# STM32H743 register map
File version: 2.4
CPU: CM7 r0p1, little endian, MPU, FPU, 4 interrupt priority bits
Registers are 32-bit, read-write, reset 0x0 unless marked. A register's access mark holds for its fields unless they carry their own. Offsets are from the block's base; [hi:lo] are bit positions; {n}, {i} and the like mark numbered series; <NAME> marks a mode.

## MDMA — MDMA（主 DMA 控制器）
Base 0x52000000
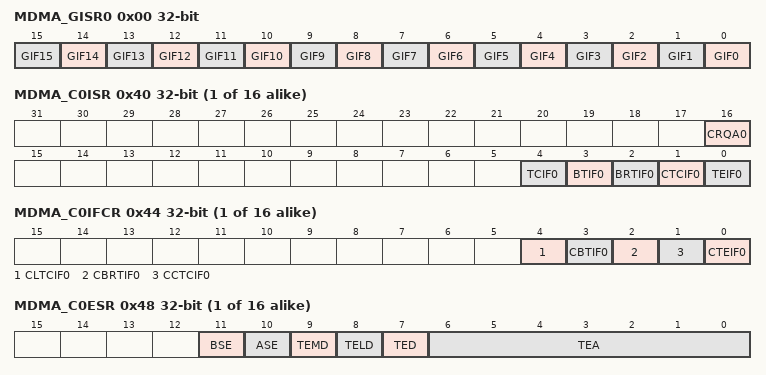
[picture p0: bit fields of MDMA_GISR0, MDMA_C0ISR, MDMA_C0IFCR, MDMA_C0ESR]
0x00 MDMA_GISR0 ro — MDMA 全局中断/状态寄存器
  [n] GIF{n} (n=0..15) — 通道 x 全局中断标志（x=...）。此位由硬件置位与复位。它是对应通道 x 所有已使能中断标志（CTCIFx、BTIFx、BRTIFx、TEIFx）的逻辑或，这些标志在中断屏蔽寄存器（CTCIEx、BTIEx、BRTIEx、TEIEx）中使能后生效。
{0x40+0x40*i} MDMA_C{i}ISR ro (i=0..15) — MDMA 通道 x 中断/状态寄存器
  [16] CRQA{i} — 通道 x 请求活跃标志
  [4] TCIF{i} — 通道 x 缓冲区传输完成
  [3] BTIF{i} — 通道 x 块传输完成中断标志。此位由硬件置位。软件向 DMA_IFCRy 寄存器的对应位写 1 可将其清零。
  [2] BRTIF{i} — 通道 x 块重复传输完成中断标志。此位由硬件置位。软件向 DMA_IFCRy 寄存器的对应位写 1 可将其清零。
  [1] CTCIF{i} — 通道 x 通道传输完成中断标志。此位由硬件置位。软件向 DMA_IFCRy 寄存器的对应位写 1 可将其清零。当最后一个块传输完成且通道已自动禁用时，CTC 置位。当通道因 EN 位写 0 而挂起时，CTC 同样置位。
  [0] TEIF{i} — 通道 x 传输错误中断标志。此位由硬件置位。软件向 DMA_IFCRy 寄存器的对应位写 1 可将其清零。
{0x44+0x40*i} MDMA_C{i}IFCR wo (i=0..15) — MDMA 通道 x 中断标志清除寄存器
  [4] CLTCIF{i} — 通道 x 清除缓冲区传输完成中断标志。向此位写 1 可将 MDMA_ISRy 寄存器中的 TCIFx 清零。
  [3] CBTIF{i} — 通道 x 清除块传输完成中断标志。向此位写 1 可将 MDMA_ISRy 寄存器中的 BTIFx 清零。
  [2] CBRTIF{i} — 通道 x 清除块重复传输完成中断标志。向此位写 1 可将 MDMA_ISRy 寄存器中的 BRTIFx 清零。
  [1] CCTCIF{i} — 通道 x 清除通道传输完成中断标志。向此位写 1 可将 MDMA_ISRy 寄存器中的 CTCIFx 清零。
  [0] CTEIF{i} — 通道 x 清除传输错误中断标志。向此位写 1 可将 MDMA_ISRy 寄存器中的 TEIFx 清零。
{0x48+0x40*i} MDMA_C{i}ESR ro (i=0..15) — MDMA 通道 x 错误状态寄存器
  [11] BSE — 块大小错误。当块大小不是源端或目的端数据大小的整数倍时，此位由硬件置位。TED 将指示问题在源端还是目的端。软件向 DMA_IFCRy 寄存器中的 CTEIFx 位写 1 可将其清零。
  [10] ASE — 地址/大小错误。当编程地址与数据大小不对齐时，此位由硬件置位。TED 将指示问题在源端还是目的端。软件向 DMA_IFCRy 寄存器中的 CTEIFx 位写 1 可将其清零。
  [9] TEMD — 传输错误（掩码数据）。当写入掩码数据发生传输错误时，此位由硬件置位。软件向 DMA_IFCRy 寄存器中的 CTEIFx 位写 1 可将其清零。
  [8] TELD — 传输错误（链接数据）。当读取块链接数据结构发生传输错误时，此位由硬件置位。软件向 DMA_IFCRy 寄存器中的 CTEIFx 位写 1 可将其清零。
  [7] TED — 传输错误方向。在 MDMA 数据传输发生错误时，此位由硬件置位与清零。
  [6:0] TEA — 传输错误地址。在 MDMA 数据传输发生错误时，这些位由硬件置位与清零，与 TED 配合使用。该字段指示引发传输/访问错误的地址的低 7 位。软件可将其（截断至缓冲区传输长度大小）与当前 SAR/DAR 值相加来还原故障地址。注意：由于 FIFO 管理机制，SAR/DAR 当前值并不反映该最后地址。SAR/DAR 仅在（缓冲区）传完 TLEN+1 字节后才更新。注意：发生链接数据错误时此字段不会置位。
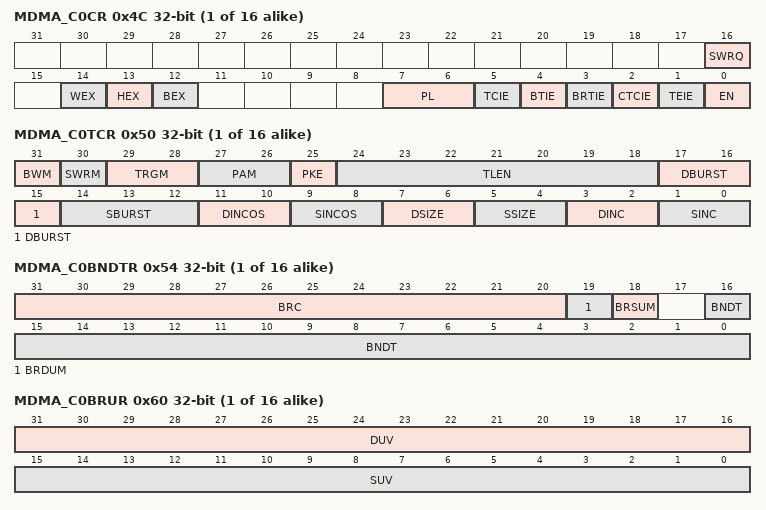
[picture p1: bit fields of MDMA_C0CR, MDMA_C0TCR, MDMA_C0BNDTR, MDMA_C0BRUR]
{0x4C+0x40*i} MDMA_C{i}CR access per field (i=0..15) — 此寄存器用于控制相应通道。
  [16] SWRQ wo — 软件请求。向此位写 1 将使 MDMA_ISRy 寄存器中的 CRQAx 置位，从而激活通道 x 的请求。注意：可通过整个 CxCR 寄存器或地址偏移为 0x4E + 0x40*通道号的 8 位/16 位寄存器来激活 SWRQ。在软件请求的情况下，不会产生应答信号（无硬件信号，也不进行 CxMAR 写访问）。
  [14] WEX rw — 字端序交换
  [13] HEX rw — 半字端序交换
  [12] BEX rw — 字节端序交换
  [7:6] PL rw — 优先级。这些位由软件置位与清零。这些位受保护，仅当 EN 为 0 时才可写入。
  [5] TCIE rw — 缓冲区传输完成中断使能。此位由软件置位与清零。
  [4] BTIE rw — 块传输中断使能。此位由软件置位与清零。
  [3] BRTIE rw — 块重复传输中断使能。此位由软件置位与清零。
  [2] CTCIE rw — 通道传输完成中断使能。此位由软件置位与清零。
  [1] TEIE rw — 传输错误中断使能。此位由软件置位与清零。
  [0] EN rw — 通道使能
{0x50+0x40*i} MDMA_C{i}TCR (i=0..15) — 此寄存器用于配置相应通道。
  [31] BWM — 缓冲写模式。此位由软件置位与清零。此位受保护，仅当 EN 为 0 时才可写入。注意：所有 MDMA 目的端访问均为不可缓存访问。
  [30] SWRM — 软件请求模式。此位由软件置位与清零。若当前有硬件或软件请求处于活跃状态，此位的变更将延迟到当前传输完成之后。若 CxMAR 包含有效地址，CxMDR 的值也将写入 CxMAR 地址。此位受保护，仅当 EN 为 0 时才可写入。
  [29:28] TRGM — 触发模式。这些位由软件置位与清零。注意：若当前块的 TRGM 为 11，则通过链接列表机制在当前块结束时加载的所有值必须保持相同的 TRGM=11 值和相同的 SWRM 值，否则结果未定义。这些位受保护，仅当 EN 为 0 时才可写入。
  [27:26] PAM — 填充/对齐模式。这些位由软件置位与清零。情况 1：源数据大小小于目的数据大小——3 种选项有效。情况 2：源数据大小大于目的数据大小——多余部分被丢弃。当 PKE = 1 或 DSIZE=SSIZE 时，这些位被忽略。这些位受保护，仅当 EN 为 0 时才可写入。
  [25] PKE — 打包使能。此位由软件置位与清零。若源数据大小小于目的数据大小，将按 PAM 值进行填充。若源数据大小大于目的数据大小，将被截断。对齐方式根据 PAM[0] 值确定。此位受保护，仅当 EN 为 0 时才可写入。
  [24:18] TLEN — 缓冲区传输长度
  [17:15] DBURST — 目的端突发传输配置
  [14:12] SBURST — 源端突发传输配置
  [11:10] DINCOS — 目的地址增量偏移
  [9:8] SINCOS — 源地址增量偏移大小
  [7:6] DSIZE — 目的数据大小。这些位由软件置位与清零。这些位受保护，仅当 EN 为 0 时才可写入。注意：若为 TCM 访问/AHB 端口编程了 11 值，将发生传输错误（TEIF 位置位）。若 DINCOS < DSIZE 且 DINC != 00，结果不可预测。注意：当目的端为 TCM/AHB 总线时（DBUS=1），禁止 DSIZE = 11（双字）。
  [5:4] SSIZE — 源数据大小。这些位由软件置位与清零。这些位受保护，仅当 EN 为 0 时才可写入。注意：若为 TCM 访问/AHB 端口编程了 11 值，将发生传输错误（TEIF 位置位）。若 SINCOS < SSIZE 且 SINC != 00，结果不可预测。注意：当源端为 TCM/AHB 总线时（SBUS=1），禁止 SSIZE = 11（双字）。
  [3:2] DINC — 目的地址增量模式。这些位由软件置位与清零。这些位受保护，仅当 EN 为 0 时才可写入。注意：当目的端为 AHB 总线时（DBUS=1），禁止 DINC = 00。
  [1:0] SINC — 源地址增量模式。这些位由软件置位与清零。这些位受保护，仅当 EN 为 0 时才可写入。注意：当源端为 AHB 总线时（SBUS=1），禁止 SINC = 00。在链接列表模式下，在一个块（单次或重复块传输模式中的最后一个块）结束时，此寄存器将从存储器（地址由当前 LAR[31:0] + 0x00 给出）重新加载。
{0x54+0x40*i} MDMA_C{i}BNDTR (i=0..15) — MDMA 通道 x 块数据传输数量寄存器
  [31:20] BRC — 块重复计数。此字段包含当前块的重复次数（0 到 4095）。通道使能后，此寄存器为只读，指示剩余块数（不含当前块）。每次完整块传输完成后此寄存器递减。最后一个块传输完成后，此寄存器可保持为零，或自动从存储器重新加载（在链接列表模式下——即链接地址有效时）。这些位受保护，仅当 EN 为 0 时才可写入。
  [19] BRDUM — 块重复目的地址更新模式。这些位受保护，仅当 EN 为 0 时才可写入。
  [18] BRSUM — 块重复源地址更新模式。这些位受保护，仅当 EN 为 0 时才可写入。
  [16:0] BNDT — 待传输数据块数量
{0x58+0x40*i} MDMA_C{i}SAR (i=0..15) — MDMA 通道 x 源地址寄存器
  [31:0] SAR — 源地址基址
{0x5C+0x40*i} MDMA_C{i}DAR (i=0..15) — MDMA 通道 x 目的地址寄存器
  [31:0] DAR — 目的地址基址
{0x60+0x40*i} MDMA_C{i}BRUR (i=0..15) — MDMA 通道 x 块重复地址更新寄存器
  [31:16] DUV — 目的地址更新值
  [15:0] SUV — 源地址更新值
{0x64+0x40*i} MDMA_C{i}LAR (i=0..15) — MDMA 通道 x 链接地址寄存器
  [31:0] LAR — 链接地址寄存器
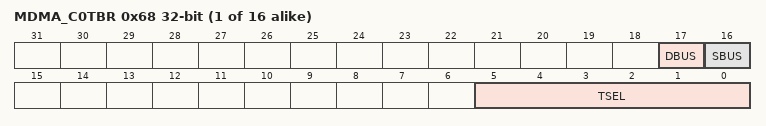
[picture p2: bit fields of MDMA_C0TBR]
{0x68+0x40*i} MDMA_C{i}TBR (i=0..15) — MDMA 通道 x 触发与总线选择寄存器
  [17] DBUS — 目的总线选择。此位受保护，仅当 EN 为 0 时才可写入。
  [16] SBUS — 源总线选择。此位受保护，仅当 EN 为 0 时才可写入。
  [5:0] TSEL — 触发选择
{0x70+0x40*i} MDMA_C{i}MAR (i=0..15) — MDMA 通道 x 掩码地址寄存器
  [31:0] MAR — 掩码地址
{0x74+0x40*i} MDMA_C{i}MDR (i=0..15) — MDMA 通道 x 掩码数据寄存器
  [31:0] MDR — 掩码数据
